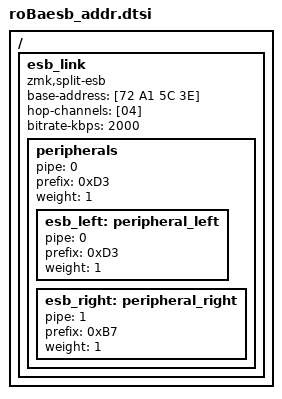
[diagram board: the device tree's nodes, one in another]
/*
 * Copyright (c) 2020 Pete Johanson
 *
 * SPDX-License-Identifier: MIT
 */

/ {
    esb_link: esb_link {
        compatible = "zmk,split-esb";
        base-address = [72 A1 5C 3E];
        hop-channels = [04];
        bitrate-kbps = <2000>;

        peripherals {
            pipe = <0>;
            prefix = <0xD3>;
            weight = <1>;

            esb_left: peripheral_left {
                pipe = <0>;
                prefix = <0xD3>;
                weight = <1>;
            };

            esb_right: peripheral_right {
                pipe = <1>;
                prefix = <0xB7>;
                weight = <1>;
            };
        };
    };
};
